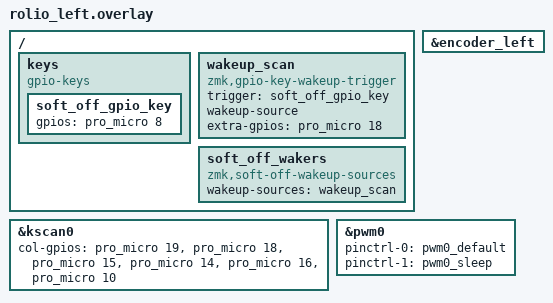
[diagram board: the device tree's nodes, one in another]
#include "rolio.dtsi"

&kscan0 {
    col-gpios
        = <&pro_micro 19 GPIO_ACTIVE_HIGH>
        , <&pro_micro 18 GPIO_ACTIVE_HIGH>
        , <&pro_micro 15 GPIO_ACTIVE_HIGH>
        , <&pro_micro 14 GPIO_ACTIVE_HIGH>
        , <&pro_micro 16 GPIO_ACTIVE_HIGH>
        , <&pro_micro 10 GPIO_ACTIVE_HIGH>
        ;
};

&encoder_left {
    status = "okay";
};

&pwm0 {
  status = "okay";
  pinctrl-0 = <&pwm0_default>;
  pinctrl-1 = <&pwm0_sleep>;
  pinctrl-names = "default", "sleep";
};

/ {
    keys {
        compatible = "gpio-keys";
        soft_off_gpio_key: soft_off_gpio_key {
            gpios = <&pro_micro 8 (GPIO_ACTIVE_HIGH | GPIO_PULL_DOWN)>;
        };
    };
};

/ {
    wakeup_scan: wakeup_scan {
        compatible = "zmk,gpio-key-wakeup-trigger";
        trigger = <&soft_off_gpio_key>;
        wakeup-source;
        extra-gpios = <&pro_micro 18 GPIO_ACTIVE_HIGH>;
    };
};

/ {
    soft_off_wakers {
        compatible = "zmk,soft-off-wakeup-sources";
        wakeup-sources = <&wakeup_scan>;
    };
};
